# STM32F7x7 register map
File version: 1.8
Registers are 32-bit, read-write, reset 0x0 unless marked. A register's access mark holds for its fields unless they carry their own. Offsets are from the block's base; [hi:lo] are bit positions; {n}, {i} and the like mark numbered series.

## SCB — System control block
Base 0xE000ED00
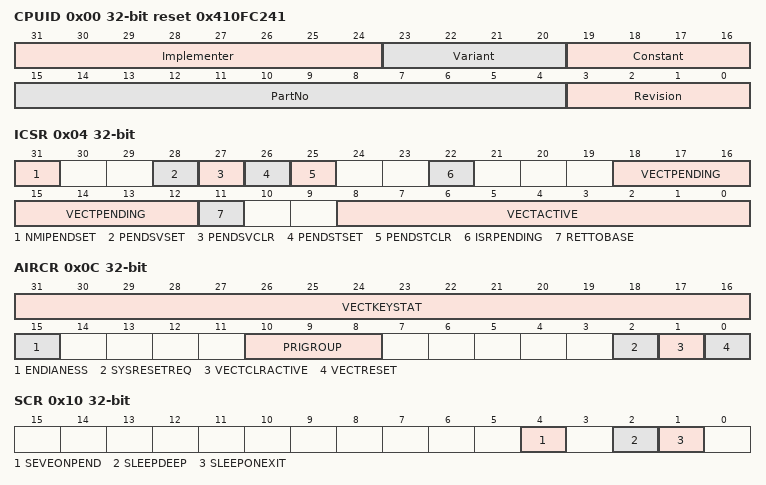
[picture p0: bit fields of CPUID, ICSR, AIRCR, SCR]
0x00 CPUID ro reset 0x410FC241 — CPUID base register
  [31:24] Implementer — Implementer code
  [23:20] Variant — Variant number
  [19:16] Constant — Reads as 0xF
  [15:4] PartNo — Part number of the processor
  [3:0] Revision — Revision number
0x04 ICSR — Interrupt control and state register
  [31] NMIPENDSET — NMI set-pending bit.
  [28] PENDSVSET — PendSV set-pending bit
  [27] PENDSVCLR — PendSV clear-pending bit
  [26] PENDSTSET — SysTick exception set-pending bit
  [25] PENDSTCLR — SysTick exception clear-pending bit
  [22] ISRPENDING — Interrupt pending flag
  [18:12] VECTPENDING — Pending vector
  [11] RETTOBASE — Return to base level
  [8:0] VECTACTIVE — Active vector
0x08 VTOR — Vector table offset register
  [29:9] TBLOFF — Vector table base offset field
0x0C AIRCR — Application interrupt and reset control register
  [31:16] VECTKEYSTAT — Register key
  [15] ENDIANESS
  [10:8] PRIGROUP
  [2] SYSRESETREQ
  [1] VECTCLRACTIVE
  [0] VECTRESET
0x10 SCR — System control register
  [4] SEVEONPEND — Send Event on Pending bit
  [2] SLEEPDEEP
  [1] SLEEPONEXIT
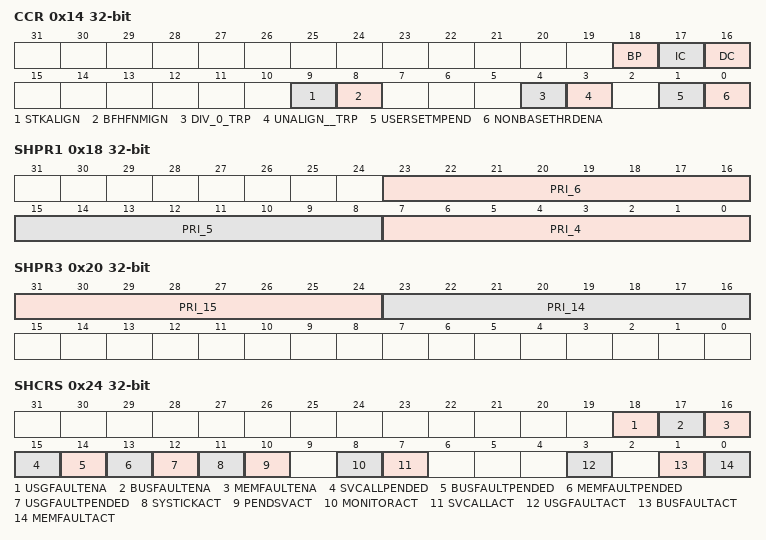
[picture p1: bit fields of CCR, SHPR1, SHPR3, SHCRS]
0x14 CCR — Configuration and control register
  [18] BP
  [17] IC
  [16] DC
  [9] STKALIGN
  [8] BFHFNMIGN
  [4] DIV_0_TRP
  [3] UNALIGN__TRP
  [1] USERSETMPEND
  [0] NONBASETHRDENA — Configures how the processor enters Thread mode
0x18 SHPR1 — System handler priority registers
  [23:16] PRI_6 — Priority of system handler 6
  [15:8] PRI_5 — Priority of system handler 5
  [7:0] PRI_4 — Priority of system handler 4
0x1C SHPR2 — System handler priority registers
  [31:24] PRI_11 — Priority of system handler 11
0x20 SHPR3 — System handler priority registers
  [31:24] PRI_15 — Priority of system handler 15
  [23:16] PRI_14 — Priority of system handler 14
0x24 SHCRS — System handler control and state register
  [18] USGFAULTENA — Usage fault enable bit
  [17] BUSFAULTENA — Bus fault enable bit
  [16] MEMFAULTENA — Memory management fault enable bit
  [15] SVCALLPENDED — SVC call pending bit
  [14] BUSFAULTPENDED — Bus fault exception pending bit
  [13] MEMFAULTPENDED — Memory management fault exception pending bit
  [12] USGFAULTPENDED — Usage fault exception pending bit
  [11] SYSTICKACT — SysTick exception active bit
  [10] PENDSVACT — PendSV exception active bit
  [8] MONITORACT — Debug monitor active bit
  [7] SVCALLACT — SVC call active bit
  [3] USGFAULTACT — Usage fault exception active bit
  [1] BUSFAULTACT — Bus fault exception active bit
  [0] MEMFAULTACT — Memory management fault exception active bit
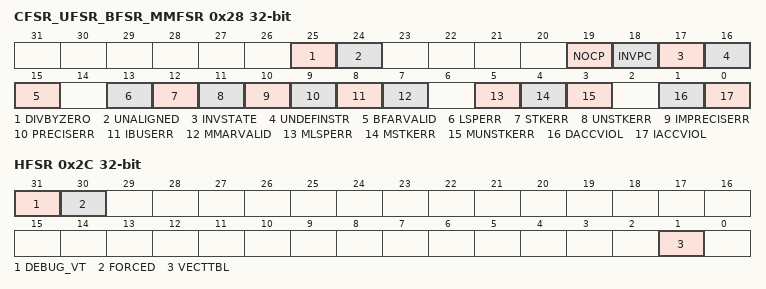
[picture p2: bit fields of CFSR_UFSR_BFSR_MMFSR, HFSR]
0x28 CFSR_UFSR_BFSR_MMFSR — Configurable fault status register
  [25] DIVBYZERO — Divide by zero usage fault
  [24] UNALIGNED — Unaligned access usage fault
  [19] NOCP — No coprocessor usage fault.
  [18] INVPC — Invalid PC load usage fault
  [17] INVSTATE — Invalid state usage fault
  [16] UNDEFINSTR — Undefined instruction usage fault
  [15] BFARVALID — Bus Fault Address Register (BFAR) valid flag
  [13] LSPERR — Bus fault on floating-point lazy state preservation
  [12] STKERR — Bus fault on stacking for exception entry
  [11] UNSTKERR — Bus fault on unstacking for a return from exception
  [10] IMPRECISERR — Imprecise data bus error
  [9] PRECISERR — Precise data bus error
  [8] IBUSERR — Instruction bus error
  [7] MMARVALID
  [5] MLSPERR
  [4] MSTKERR
  [3] MUNSTKERR
  [1] DACCVIOL
  [0] IACCVIOL
0x2C HFSR — Hard fault status register
  [31] DEBUG_VT — Reserved for Debug use
  [30] FORCED — Forced hard fault
  [1] VECTTBL — Vector table hard fault
0x34 MMFAR — Memory management fault address register
  [31:0] ADDRESS — Memory management fault address
0x38 BFAR — Bus fault address register
  [31:0] ADDRESS — Bus fault address

## PF — Processor features
Base 0xE000ED78
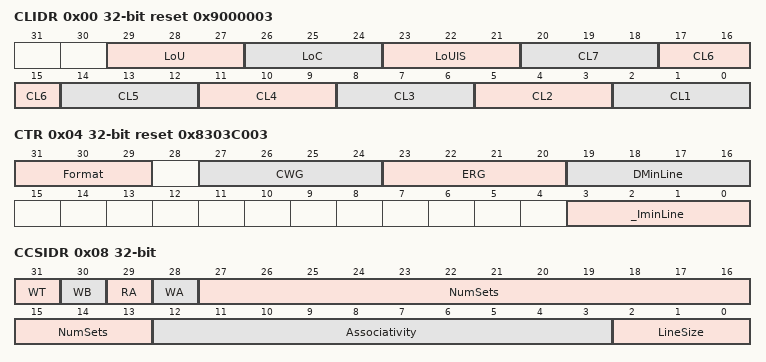
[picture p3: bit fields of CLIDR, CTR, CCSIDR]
0x00 CLIDR ro reset 0x9000003 — Cache Level ID register
  [29:27] LoU, [26:24] LoC, [23:21] LoUIS, [3n-1:3n-3] CL{n} (n=1..7)
0x04 CTR ro reset 0x8303C003 — Cache Type register
  [31:29] Format, [27:24] CWG, [23:20] ERG, [19:16] DMinLine, [3:0] _IminLine
0x08 CCSIDR ro — Cache Size ID register
  [31] WT, [30] WB, [29] RA, [28] WA, [27:13] NumSets, [12:3] Associativity, [2:0] LineSize

## AC — Access control
Base 0xE000EF90
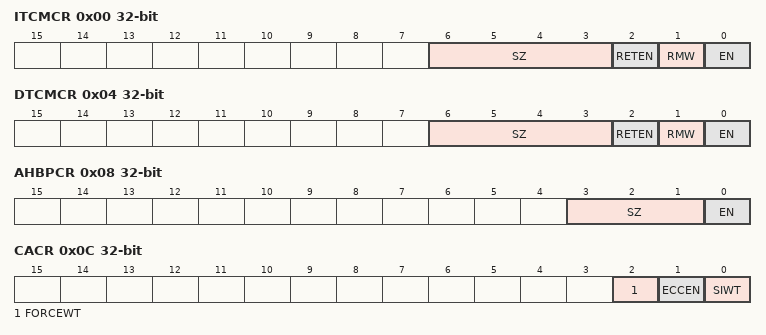
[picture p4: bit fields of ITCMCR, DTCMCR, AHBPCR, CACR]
0x00 ITCMCR — Instruction and Data Tightly-Coupled Memory Control Registers
  [6:3] SZ, [2] RETEN, [1] RMW, [0] EN
0x04 DTCMCR — Instruction and Data Tightly-Coupled Memory Control Registers
  [6:3] SZ, [2] RETEN, [1] RMW, [0] EN
0x08 AHBPCR — AHBP Control register
  [3:1] SZ, [0] EN
0x0C CACR — Auxiliary Cache Control register
  [2] FORCEWT, [1] ECCEN, [0] SIWT
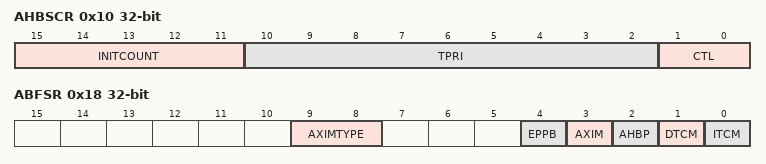
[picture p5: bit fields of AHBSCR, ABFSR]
0x10 AHBSCR — AHB Slave Control register
  [15:11] INITCOUNT, [10:2] TPRI, [1:0] CTL
0x18 ABFSR — Auxiliary Bus Fault Status register
  [9:8] AXIMTYPE, [4] EPPB, [3] AXIM, [2] AHBP, [1] DTCM, [0] ITCM

## DBGMCU — MCU debug component
Base 0xE0042000
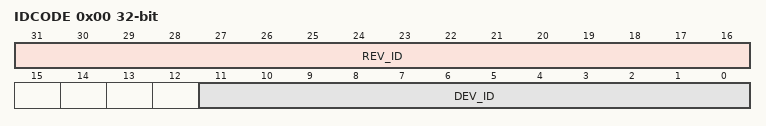
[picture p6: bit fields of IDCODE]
0x00 IDCODE ro — DBGMCU_IDCODE
  [31:16] REV_ID — Revision identifie
  [11:0] DEV_ID — Device identifier
